# ISS_ISP5_SYS1 register map
Vendor: Texas Instruments
Peripheral module from a debugger description file (folder omap4430).
Registers are 32-bit, access not given, reset 0x0 unless marked. A register's access mark holds for its fields unless they carry their own. Offsets are as the file gives them; lines under a group give offsets from that group; [hi:lo] are bit positions; {n}, {i} and the like mark numbered series; 'fields as' and 'values as' point back to an identical list; <NAME> marks a mode.

## ISS_ISP5_SYS1 (part 1 of 2)
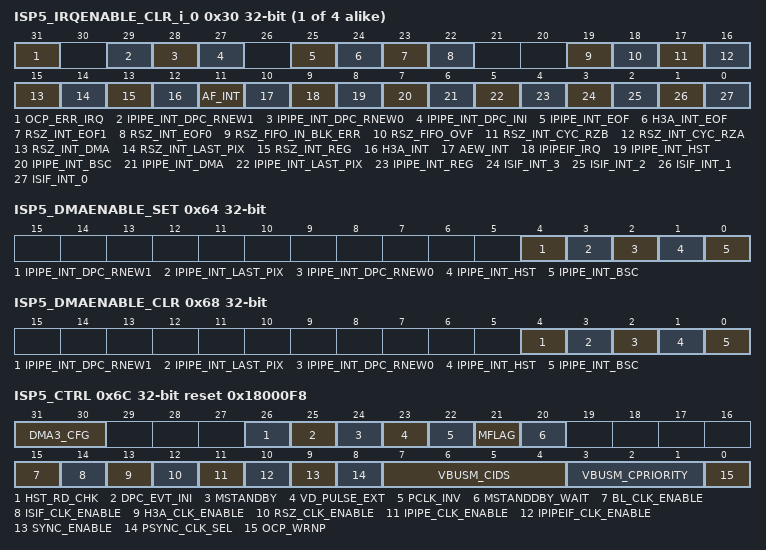
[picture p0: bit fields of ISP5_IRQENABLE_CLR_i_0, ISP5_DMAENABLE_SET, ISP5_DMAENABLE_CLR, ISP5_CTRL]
{0x30+0x10*i} ISP5_IRQENABLE_CLR_i_{i} (i=0..3) — Per-event interrupt enable bit vector. Write 1 to clear (disable interrupt). Readout equal to corresponding _SET register. The ISP outputs four interrupt lines, ISP_IRQ0 to ISP_IRQ3. Any internal ISP event can be merged on the four lines. A same event must be enabled on only one interrupt line.
  [31] OCP_ERR_IRQ — An OCP error has been received on the ISP master port. (access RW W1toClr)
    0=OCP_ERR_IRQ_0_w (No action); 1=OCP_ERR_IRQ_1_w (Disable interrupt); 1=OCP_ERR_IRQ_1_r (Interrupt enabled); 0=OCP_ERR_IRQ_0_r (Interrupt disabled (masked))
  [29] IPIPE_INT_DPC_RNEW1 — (access RW W1toClr)
    0=IPIPE_INT_DPC_RNEW1_0_w (No action); 1=IPIPE_INT_DPC_RNEW1_1_w (Disable interrupt); 1=IPIPE_INT_DPC_RNEW1_1_r (Interrupt enabled); 0=IPIPE_INT_DPC_RNEW1_0_r (Interrupt disabled (masked))
  [28] IPIPE_INT_DPC_RNEW0 — (access RW W1toClr)
    0=IPIPE_INT_DPC_RNEW0_0_w (No action); 1=IPIPE_INT_DPC_RNEW0_1_w (Disable interrupt); 1=IPIPE_INT_DPC_RNEW0_1_r (Interrupt enabled); 0=IPIPE_INT_DPC_RNEW0_0_r (Interrupt disabled (masked))
  [27] IPIPE_INT_DPC_INI — (access RW W1toClr)
    0=IPIPE_INT_DPC_INI_0_w (No action); 1=IPIPE_INT_DPC_INI_1_w (Disable interrupt); 1=IPIPE_INT_DPC_INI_1_r (Interrupt enabled); 0=IPIPE_INT_DPC_INI_0_r (Interrupt disabled (masked))
  [25] IPIPE_INT_EOF rw
    0=IPIPE_INT_EOF_0_w (No action); 1=IPIPE_INT_EOF_1_w (Disable interrupt); 1=IPIPE_INT_EOF_1_r (Interrupt enabled); 0=IPIPE_INT_EOF_0_r (Interrupt disabled (masked))
  [24] H3A_INT_EOF rw
    0=H3A_INT_EOF_0_w (No action); 1=H3A_INT_EOF_1_w (Disable interrupt); 1=H3A_INT_EOF_1_r (Interrupt enabled); 0=H3A_INT_EOF_0_r (Interrupt disabled (masked))
  [23] RSZ_INT_EOF1 rw — RESIZER module event: This event signals that the BL has received the EOF signal from the resizer B engine which happens one the last transfer in the frame has happened. Note that because the BL has FIFOs it may take some additional time before true data transfer completion to memory.
    0=RSZ_INT_EOF1_0_w (No action); 1=RSZ_INT_EOF1_1_w (Disable interrupt); 1=RSZ_INT_EOF1_1_r (Interrupt enabled); 0=RSZ_INT_EOF1_0_r (Interrupt disabled (masked))
  [22] RSZ_INT_EOF0 rw — RESIZER module event: This event signals that the BL has received the EOF signal from the resizer A engine which happens one the last transfer in the frame has happened. Note that because the BL has FIFOs it may take some additional time before true data transfer completion to memory.
    0=RSZ_INT_EOF0_0_w (No action); 1=RSZ_INT_EOF0_1_w (Disable interrupt); 1=RSZ_INT_EOF0_1_r (Interrupt enabled); 0=RSZ_INT_EOF0_0_r (Interrupt disabled (masked))
  [19] RSZ_FIFO_IN_BLK_ERR — This event signals that the minimum vertical blanking period has not been respected causing errors in the input data buffering submodule. This event will be triggered when the rsz_int_reg event of frame N is triggered before the rsz_int_dma of frame N + 1. This event would typically happen at the transition between two frames because there is not enough vertical blanking between frames: the firmware must take care to ensure enough vertical blanking. The hardware cannot recover from this error. It will be required to perform a reset of the IP. (access RW W1toClr)
    0=RSZ_FIFO_IN_BLK_ERR_0_w (No action); 1=RSZ_FIFO_IN_BLK_ERR_1_w (Disable interrupt); 1=RSZ_FIFO_IN_BLK_ERR_1_r (Interrupt enabled); 0=RSZ_FIFO_IN_BLK_ERR_0_r (Interrupt disabled (masked))
  [18] RSZ_FIFO_OVF — RESIZER module event: This event signals that overflow happened in the input data buffering submodule or in the RSZ output interface.. This event would typically happen because the video port pixel clock is too high. (access RW W1toClr)
    0=RSZ_FIFO_OVF_0_w (No action); 1=RSZ_FIFO_OVF_1_w (Disable interrupt); 1=RSZ_FIFO_OVF_1_r (Interrupt enabled); 0=RSZ_FIFO_OVF_0_r (Interrupt disabled (masked))
  [17] RSZ_INT_CYC_RZB — RESIZER module event: This event is the circular interrupt for RESIZER #B. An event can be triggered every time that RSZ_IRQ_RZB output lines have been written out to the RZB_SDR_Y buffer. The range can go from 1 to 8192 lines. Usually, this value should be such that the circular buffer vertical size (set by the RZB_SDR_Y_PTR_E register) is a multiple of RSZ_IRQ_RZB. Note that at the time the interrupt is triggered, the actual data write has not taken place. It may take a few hundred of cycles to complete the data write into system memory. This is not an issue since the start of the buffer is read first. (access RW W1toClr)
    0=RSZ_INT_CYC_RZB_0_w (No action); 1=RSZ_INT_CYC_RZB_1_w (Disable interrupt); 1=RSZ_INT_CYC_RZB_1_r (Interrupt enabled); 0=RSZ_INT_CYC_RZB_0_r (Interrupt disabled (masked))
  [16] RSZ_INT_CYC_RZA — RESIZER module event: This event is the circular interrupt for RESIZER #A. An event can be triggered every time that RSZ_IRQ_RZA output lines have been written out to the RZA_SDR_Y buffer. The range can go from 1 to 8192 lines. Usually, the circular buffer vertical size (set by the RZA_SDR_Y_PTR_E register) should be a multiple of RSZ_IRQ_RZA. Note that at the time the interrupt is triggered, the actual data write has not taken place. It may take a few hundred of cycles to complete the data write into system memory. This is not an issue since the start of the buffer is read first. (access RW W1toClr)
    0=RSZ_INT_CYC_RZA_0_w (No action); 1=RSZ_INT_CYC_RZA_1_w (Disable interrupt); 1=RSZ_INT_CYC_RZA_1_r (Interrupt enabled); 0=RSZ_INT_CYC_RZA_0_r (Interrupt disabled (masked))
  [15] RSZ_INT_DMA — RESIZER module event: This event is triggered when the last EOF (of the two MTC interfaces) is sent out to the BL and that the resizer core has returned to idle. rsz_int_dma is a true indication that all processing is finished for the particular frame on both resizer engines. (access RW W1toClr)
    0=RSZ_INT_DMA_0_w (No action); 1=RSZ_INT_DMA_1_w (Disable interrupt); 1=RSZ_INT_DMA_1_r (Interrupt enabled); 0=RSZ_INT_DMA_0_r (Interrupt disabled (masked))
  [14] RSZ_INT_LAST_PIX — RESIZER module event: This event is triggered when the last pixel of the valid area is received. (access RW W1toClr)
    0=RSZ_INT_LAST_PIX_0_w (No action); 1=RSZ_INT_LAST_PIX_1_w (Disable interrupt); 1=RSZ_INT_LAST_PIX_1_r (Interrupt enabled); 0=RSZ_INT_LAST_PIX_0_r (Interrupt disabled (masked))
  [13] RSZ_INT_REG — RESIZER module event: This event is triggered when the first pixel of the valid area is received. Shadowed registers can be updated at any time but the new value will take effect on the next rsz_int_reg event. (access RW W1toClr)
    0=RSZ_INT_REG_0_w (No action); 1=RSZ_INT_REG_1_w (Disable interrupt); 1=RSZ_INT_REG_1_r (Interrupt enabled); 0=RSZ_INT_REG_0_r (Interrupt disabled (masked))
  [12] H3A_INT — (access RW W1toClr)
    0=H3A_INT_0_w (No action); 1=H3A_INT_1_w (Disable interrupt); 1=H3A_INT_1_r (Interrupt enabled); 0=H3A_INT_0_r (Interrupt disabled (masked))
  [11] AF_INT — (access RW W1toClr)
    0=AF_INT_0_w (No action); 1=AF_INT_1_w (Disable interrupt); 1=AF_INT_1_r (Interrupt enabled); 0=AF_INT_0_r (Interrupt disabled (masked))
  [10] AEW_INT — (access RW W1toClr)
    0=AEW_INT_0_w (No action); 1=AEW_INT_1_w (Disable interrupt); 1=AEW_INT_1_r (Interrupt enabled); 0=AEW_INT_0_r (Interrupt disabled (masked))
  [9] IPIPEIF_IRQ — IPIPEIF module interrupt (access RW W1toClr)
    0=IPIPEIF_IRQ_0_w (No action); 1=IPIPEIF_IRQ_1_w (Disable interrupt); 1=IPIPEIF_IRQ_1_r (Interrupt enabled); 0=IPIPEIF_IRQ_0_r (Interrupt disabled (masked))
  [8] IPIPE_INT_HST — (access RW W1toClr)
    0=IPIPE_INT_HST_0_w (No action); 1=IPIPE_INT_HST_1_w (Disable interrupt); 1=IPIPE_INT_HST_1_r (Interrupt enabled); 0=IPIPE_INT_HST_0_r (Interrupt disabled (masked))
  [7] IPIPE_INT_BSC — (access RW W1toClr)
    0=IPIPE_INT_BSC_0_w (No action); 1=IPIPE_INT_BSC_1_w (Disable interrupt); 1=IPIPE_INT_BSC_1_r (Interrupt enabled); 0=IPIPE_INT_BSC_0_r (Interrupt disabled (masked))
  [6] IPIPE_INT_DMA — (access RW W1toClr)
    0=IPIPE_INT_DMA_0_w (No action); 1=IPIPE_INT_DMA_1_w (Disable interrupt); 1=IPIPE_INT_DMA_1_r (Interrupt enabled); 0=IPIPE_INT_DMA_0_r (Interrupt disabled (masked))
  [5] IPIPE_INT_LAST_PIX — (access RW W1toClr)
    0=IPIPE_INT_LAST_PIX_0_w (No action); 1=IPIPE_INT_LAST_PIX_1_w (Disable interrupt); 1=IPIPE_INT_LAST_PIX_1_r (Interrupt enabled); 0=IPIPE_INT_LAST_PIX_0_r (Interrupt disabled (masked))
  [4] IPIPE_INT_REG — (access RW W1toClr)
    0=IPIPE_INT_REG_0_w (No action); 1=IPIPE_INT_REG_1_w (Disable interrupt); 1=IPIPE_INT_REG_1_r (Interrupt enabled); 0=IPIPE_INT_REG_0_r (Interrupt disabled (masked))
  [3] ISIF_INT_3 — Set this bit to disable the LSC interrupt issued by the 2D-LSC block. Four types of 2D-LSC can be generated and mapped to the INT_3 line. For more information, see, (access RW W1toClr)
    0=ISIF_INT_3_0_w (No action); 1=ISIF_INT_3_1_w (Disable interrupt); 1=ISIF_INT_3_1_r (Interrupt enabled); 0=ISIF_INT_3_0_r (Interrupt disabled (masked))
  [2] ISIF_INT_2 — VD interrupt 2 event. Set this bit to disable the interrupt mapped to the INT_2 line. This interrupt is set based on the VD pulse position after receiving a configured number of horizontal pulse signals. For more information, see, (access RW W1toClr)
    0=ISIF_INT_2_0_w (No action); 1=ISIF_INT_2_1_w (Disable interrupt); 1=ISIF_INT_2_1_r (Interrupt enabled); 0=ISIF_INT_2_0_r (Interrupt disabled (masked))
  [1] ISIF_INT_1 — VD interrupt 1 event. Set this bit to disable the interrupt mapped to the INT_1 line. This interrupt is set based on the VD pulse position after receiving a configured number of horizontal pulse signals. For more information, see, (access RW W1toClr)
    0=ISIF_INT_1_0_w (No action); 1=ISIF_INT_1_1_w (Disable interrupt); 1=ISIF_INT_1_1_r (Interrupt enabled); 0=ISIF_INT_1_0_r (Interrupt disabled (masked))
  [0] ISIF_INT_0 — VD interrupt 0 event. Set this bit to disable the interrupt mapped to the INT_0 line. This interrupt is set based on the VD pulse position after receiving a configured number of horizontal pulse signals. For more information, see, (access RW W1toClr)
    0=ISIF_INT_0_0_w (No action); 1=ISIF_INT_0_1_w (Disable interrupt); 1=ISIF_INT_0_1_r (Interrupt enabled); 0=ISIF_INT_0_0_r (Interrupt disabled (masked))
0x64 ISP5_DMAENABLE_SET — Per-line DMA enable bit vector Write 1 to set (enable DMA request generation). Readout equal to corresponding _CLR register.
  [4] IPIPE_INT_DPC_RNEW1 — Enable for ISP DMA request generation on line #2 This DMA request must be set to transfer the DPC data from memory to the IPIPE internal RAM. (access RW W1toSet)
    0=IPIPE_INT_DPC_RNEW1_0_w (No action); 1=IPIPE_INT_DPC_RNEW1_1_w (Enable DMA); 1=IPIPE_INT_DPC_RNEW1_1_r (DMA enabled); 0=IPIPE_INT_DPC_RNEW1_0_r (DMA disabled)
  [3] IPIPE_INT_LAST_PIX — Enable for ISP DMA request generation on line #3 This DMA request must be set to transfer the GAMMA data from memory to the IPIPE internal RAM or to initialize the DPC table. One must set the ISP5_CTRL.DMA3_CFG register before enabling this DMA request. (access RW W1toSet)
    0=IPIPE_INT_LAST_PIX_0_w (No action); 1=IPIPE_INT_LAST_PIX_1_w (Enable DMA); 1=IPIPE_INT_LAST_PIX_1_r (DMA enabled); 0=IPIPE_INT_LAST_PIX_0_r (DMA disabled)
  [2] IPIPE_INT_DPC_RNEW0 — Enable for ISP DMA request generation on line #2 This DMA request must be set to transfer the DPC data from memory to the IPIPE internal RAM. (access RW W1toSet)
    0=IPIPE_INT_DPC_RNEW0_0_w (No action); 1=IPIPE_INT_DPC_RNEW0_1_w (Enable DMA); 1=IPIPE_INT_DPC_RNEW0_1_r (DMA enabled); 0=IPIPE_INT_DPC_RNEW0_0_r (DMA disabled)
  [1] IPIPE_INT_HST — Enable for ISP DMA request generation on line #1 This DMA request must be set to transfer the HIST data from the IPIPE internal RAM to memory. (access RW W1toSet)
    0=IPIPE_INT_HST_0_w (No action); 1=IPIPE_INT_HST_1_w (Enable DMA); 1=IPIPE_INT_HST_1_r (DMA enabled); 0=IPIPE_INT_HST_0_r (DMA disabled)
  [0] IPIPE_INT_BSC — Enable for ISP DMA request generation on line #0 This DMA request must be set to transfer the BSC data from the IPIPE internal RAM to memory. (access RW W1toSet)
    0=IPIPE_INT_BSC_0_w (No action); 1=IPIPE_INT_BSC_1_w (Enable DMA); 1=IPIPE_INT_BSC_1_r (DMA enabled); 0=IPIPE_INT_BSC_0_r (DMA disabled)
0x68 ISP5_DMAENABLE_CLR — Per-line DMA clear bit vector Write 1 to clear (disable DMA request generation). Readout equal to corresponding _SET register.
  [4] IPIPE_INT_DPC_RNEW1 — Clear for ISP DMA request generation on line ISS_DMA2. This DMA request must be set to transfer the DPC data from memory to the IPIPE internal RAM. (access RW W1toClr)
    0=IPIPE_INT_DPC_RNEW1_0_w (No action); 1=IPIPE_INT_DPC_RNEW1_1_w (Disable DMA); 1=IPIPE_INT_DPC_RNEW1_1_r (DMA enabled); 0=IPIPE_INT_DPC_RNEW1_0_r (DMA disabled)
  [3] IPIPE_INT_LAST_PIX — Clear for ISP DMA request generation on ISS_DMA3. This DMA request must be set to transfer the GAMMA data from memory to the IPIPE internal RAM. (access RW W1toClr)
    0=IPIPE_INT_LAST_PIX_0_w (No action); 1=IPIPE_INT_LAST_PIX_1_w (Disable DMA); 1=IPIPE_INT_LAST_PIX_1_r (DMA enabled); 0=IPIPE_INT_LAST_PIX_0_r (DMA disabled)
  [2] IPIPE_INT_DPC_RNEW0 — Clear for ISP DMA request generation on ISS_DMA2. This DMA request must be set to transfer the DPC data from memory to the IPIPE internal RAM. (access RW W1toClr)
    0=IPIPE_INT_DPC_RNEW0_0_w (No action); 1=IPIPE_INT_DPC_RNEW0_1_w (Disable DMA); 1=IPIPE_INT_DPC_RNEW0_1_r (DMA enabled); 0=IPIPE_INT_DPC_RNEW0_0_r (DMA disabled)
  [1] IPIPE_INT_HST — Clear for ISP DMA request generation on ISS_DMA1. This DMA request must be set to transfer the HIST data from the IPIPE internal RAM to memory. (access RW W1toClr)
    0=IPIPE_INT_HST_0_w (No action); 1=IPIPE_INT_HST_1_w (Disable DMA); 1=IPIPE_INT_HST_1_r (DMA enabled); 0=IPIPE_INT_HST_0_r (DMA disabled)
  [0] IPIPE_INT_BSC — Clear for ISP DMA request generation on ISS_DMA0. This DMA request must be set to transfer the BSC data from the IPIPE internal RAM to memory. (access RW W1toClr)
    0=IPIPE_INT_BSC_0_w (No action); 1=IPIPE_INT_BSC_1_w (Disable DMA); 1=IPIPE_INT_BSC_1_r (DMA enabled); 0=IPIPE_INT_BSC_0_r (DMA disabled)
0x6C ISP5_CTRL access per field reset 0x18000F8 (reset mask 0xFFEFFFFF) — ISP5 CONTROL REGISTER
  [31:30] DMA3_CFG rw — This bit field selects the DMA transfer configuration which is used with the ISS_DMA3 DMA request signal. This DMA request is generated from IPIPE_INT_LAST_PIXEL event. One can choose to use this DMA request to transfer the DPC initialization data, the gamma table, or both.
    0=No DMA request associated with ISS_DMA3; 1=DPC DMA request associated with ISS_DMA3. Expected DMA transfer size is 2KB in the range 0x8000-0x87FF. DPC_EVT_INI must be set to 0.; 3=DPC + GAMMA DMA request associated with ISS_DMA3. Expected DMA transfer size is 8KB in the range 0x8000-0x87FF and 0xA800-0xBFFF. DPC_EVT_INI must be set to 0.; 2=GAMMA DMA request associated with ISS_DMA3. Expected DMA transfer size is 6KB in the range 0xA800-0xBFFF.
  [26] HST_RD_CHK rw — When the HISTOGRAM computation is enabled and the HST DMA request is not used to read out the data, this register ensures that the data is read fast enough, else an interruptISP5_IRQSTATUS2_i[5] IPIPE_HST_ERR is triggered. The hardware sets automatically this bit to 1 when software can start reading the memory. .
    0=HST_RD_CHK_0_w (Clears the signal to avoid error generation. The software must write this bit to 0 after the last data read.); 1=HST_RD_CHK_1_w (Reserved); 1=HST_RD_CHK_1_r (The MPU can read the data from the memory. Needs to complete fast enough to avoid the interrupt generation.); 0=HST_RD_CHK_0_r (No interrupt generation can happen)
  [25] DPC_EVT_INI rw — Select the IPIPE module event to be used to generate the DMA requests for the DPC submodule.
    0=IPIPE_INT_LAST_PIX event is selected; 1=IPIPE_INT_DPC_INI event is selected
  [24] MSTANDBY rw — MStandby signal assertion and de-assertion control for power management transitions. After software reset, this bit is asserted. Write '1' to transition from normal mode to idle mode. The firmware needs to ensure that no more ISP processing is ongoing before setting up this bit. Write '0' to transition from idle mode to normal mode. The software should poll ISP5_CTRL.MSTANDBY_WAIT = 0 after writing ISP5_CTRL.MSTANDBY = 0 in a transition from idle to normal mode.
    0=De-assert MStandby signal. May not be immediate due to power management handshaking btw the MStandby and Wait signals.; 1=Assert MStandby signal
  [23] VD_PULSE_EXT rw — VD pulse extension enable This bit enables or disables the VD extension bridge. By default, the bridge is enabled. At ISS level, it is expected that ISP5_CTRL.VD_PULSE_EXT = 1 when the VPORT gets data from the CSI2 RX module and ISP5_CTRL.VD_PULSE_EXT = 0 when the VPORT gets data from the parallel interface or the CCP2 RX module. There must be at least three clock cycles between the time this bit is modified and the HD/VD pulse for start of frame comes.
    0=Disabled; 1=Enabled
  [22] PCLK_INV rw — Pixel clock inversion This bit enables or disables pixel clock inversion. The ISP always samples the data on the rising edge of the pixel clock. Enabling the inversion shifts the resampling period by 1/2 a pixel clock period.
    0=Normal; 1=Inversed
  [21] MFLAG rw — MFlag signal generation control This bit controls how the OCP MFlag signal is generated on the ISS NOC. 0x0: The MFlag value is dynamic. 0x1: The MFlag value is static. The value is set with the ISP5_CTRL[3:1] VBUSM_CPRIORITY.
  [20] MSTANDDBY_WAIT ro — MStandby / Wait power management status bit. The power management framework of the ISP is based on the handshaking of the MStandby and Wait signals. The software is not supposed to write inside the ISP slave port and initiate traffic when ISP5_CTRL.MSTANDBY bit is written. The software can poll this bit to know when Wait signal is deasserted.
    1=MSTANDDBY_WAIT_1_r (MStandby signal is asserted.); 0=MSTANDDBY_WAIT_0_r (MStandby signal is deasserted.)
  [15] BL_CLK_ENABLE rw — BL clock enable
    0=Disable; 1=Enable
  [14] ISIF_CLK_ENABLE rw — ISIF clock enable The ISP will return OCP_ERROR if one tries to program the module MMR or memory when the clock is disabled. There must be at least three clock cycles between the time this bit is modified and the HD/VD pulse for start of frame comes.
    0=Disable; 1=Enable
  [13] H3A_CLK_ENABLE rw — H3A clock enable The ISP will return OCP_ERROR if one tries to program the module MMR or memory when the clock is disabled.
    0=Disable; 1=Enable
  [12] RSZ_CLK_ENABLE rw — RESIZER clock enable The ISP will return OCP_ERROR if one tries to program the module MMR or memory when the clock is disabled.
    0=Disable; 1=Enable
  [11] IPIPE_CLK_ENABLE rw — IPIPE clock enable The ISP will return OCP_ERROR if one tries to program the module MMR or memory when the clock is disabled.
    0=Disable; 1=Enable
  [10] IPIPEIF_CLK_ENABLE rw — IPIPEIF clock enable The ISP will return OCP_ERROR if one tries to program the module MMR or memory when the clock is disabled.
    0=Disable; 1=Enable
  [9] SYNC_ENABLE rw — PCLK Sync module enable. This bit may only be modified when the video port is not receiving data such as when data is read from the IPIPEIF module memory read port.
    0=Disable; 1=Enable
  [8] PSYNC_CLK_SEL rw — PCLK Sync clock select. This bit selects the clock which is used to resynchronize the input pixel clock.
    0=GCK_MMR. Can be used if the input pixel clock is always lower than 100 MHz.; 1=ISS_FCLK. must be used if the pixel clock is higher than 100 MHz.
  [7:4] VBUSM_CIDS rw — BL MAX VBUSM CIDs The BL module supports up to 16 CIDs/tags. This bit field sets up the maximum number of CISs/tags that the BL can use. The actual number of CIDs/tags is setup by VBUSM_CIDS + 1. Tag number 0 to VBUSM_CIDS are used.
  [3:1] VBUSM_CPRIORITY rw — BL VBUSM priority setting
    {v}=Normal Priority VBUSM cpriority[2:0] = {v} (v=4..7); 1=High Priority VBUSM cpriority[2:0] = 1; 0=High Priority VBUSM cpriority[2:0] = 0; 2=Medium Priority VBUSM cpriority[2:0] = 2; 3=Medium Priority VBUSM cpriority[2:0] = 3
  [0] OCP_WRNP rw — ISP OCP master port non-posted write control.
    0=All writes are non posted; 1=All writes are posted
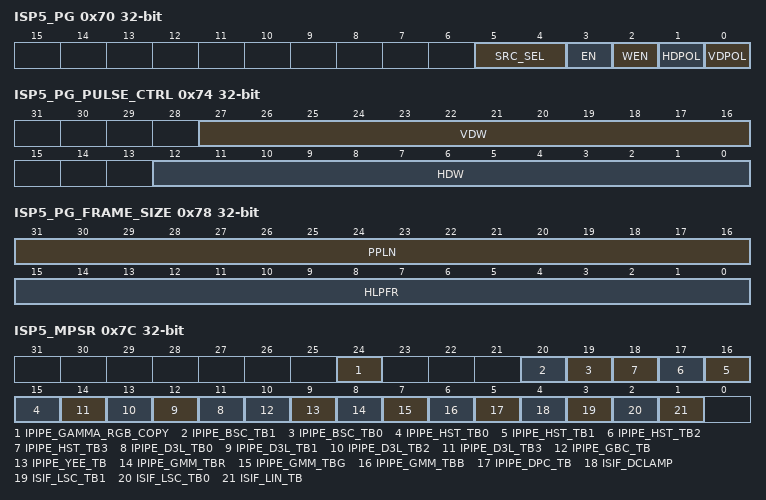
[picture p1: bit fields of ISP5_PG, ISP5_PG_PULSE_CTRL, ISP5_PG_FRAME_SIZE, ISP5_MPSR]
0x70 ISP5_PG access per field — PATTERN GENERATOR REGISTER
  [5:4] SRC_SEL rw — Input mux selection
    0=ISP video port is selected; 3=Pattern generator is selected
  [3] EN rw
    0=Pattern generator off; 1=Enable pattern generator
  [2] WEN rw
    0=WEN is always activated; 1=WEN is on 8 cycles and off 8 cycles
  [1] HDPOL rw
    0=Active high; 1=Active low
  [0] VDPOL rw
    0=Active high; 1=Active low
0x74 ISP5_PG_PULSE_CTRL access per field — PATTERN GENERATOR REGISTER
  [27:16] VDW rw — Pattern generator VD width Width = VDW+1
  [12:0] HDW rw — Pattern generator HD width Width = HDW+1
0x78 ISP5_PG_FRAME_SIZE rw — PATTERN GENERATOR REGISTER
  [31:16] PPLN — Pattern Generator: pixels per line, PPLN+1
  [15:0] HLPFR — Pattern Generator: half lines per frame, HLPFR+1
0x7C ISP5_MPSR access per field — ISP memory access register. One need to pay attention when setting the bit fields in this register such that there is no conflict between the CPU and module accesses. Usually, the ISP modules must have access to the memories and it is only when the ISP is idle (vertical blanking period or module disabled that the CPU can access the memories.
  [24] IPIPE_GAMMA_RGB_COPY rw — GAMMA table RGB Copy This bit must be enable when one wants to use the same Gamma table for the R, G and B color components. When the CPU writes the R table, it is automatically copied to the G and B tables if this bit is set.
    0=Copy disable Independent RGB gamma table; 1=Copy enable Common RGB Gamma table
  [20] IPIPE_BSC_TB1 rw — IPIPE BSC TB1 memory access priority This memory is expected to be read by the CPU or the DMA to get BSC information during vertical blanking period.
    0=MODULE access has higher priority; 1=CPU access has higher priority
  [19] IPIPE_BSC_TB0 rw — IPIPE BSC TB0 memory access priority This memory is expected to be read by the CPU or the DMA to get BSC information during vertical blanking period.
    values as IPIPE_BSC_TB1
  [n+15] IPIPE_HST_TB{n} rw (n=0..3) — IPIPE histogram memory #{n} access priority This memory is expected to be read by the CPU or the DMA to get HST information during vertical blanking period.
    values as IPIPE_BSC_TB1
  [n+11] IPIPE_D3L_TB{n} rw (n=0..3) — D3L TB{n} memory access priority This memory is expected to be written during ISP initialization and potentially updated during vertical blanking periods.
    values as IPIPE_BSC_TB1
  [10] IPIPE_GBC_TB rw — IPIPE GBC TB memory access priority This memory is expected to be written during ISP initialization and potentially updated during vertical blanking periods.
    values as IPIPE_BSC_TB1
  [9] IPIPE_YEE_TB rw — YEE TB memory access priority This memory is expected to be written during ISP initialization and potentially updated during vertical blanking periods.
    values as IPIPE_BSC_TB1
  [8] IPIPE_GMM_TBR rw — IPIPE Gamma LUT R memory arbitration This memory is expected to be written during ISP initialization and potentially updated during vertical blanking periods.
    values as IPIPE_BSC_TB1
  [7] IPIPE_GMM_TBG rw — IPIPE Gamma LUT G memory arbitration This memory is expected to be written during ISP initialization and potentially updated during vertical blanking periods.
    values as IPIPE_BSC_TB1
  [6] IPIPE_GMM_TBB rw — IPIPE Gamma LUT B memory arbitration This memory is expected to be written during ISP initialization and potentially updated during vertical blanking periods.
    values as IPIPE_BSC_TB1
  [5] IPIPE_DPC_TB rw — IPIPE defect pixel memory arbitration This memory is expected to be written during ISP initialization and potentially updated during vertical blanking periods.
    values as IPIPE_BSC_TB1
  [4] ISIF_DCLAMP rw — ISIF DC accumulation memory arbitration This memory is expected to be written during ISP initialization and potentially updated during vertical blanking periods.
    values as IPIPE_BSC_TB1
  [3] ISIF_LSC_TB1 rw — ISIF LSC memory 1 access This memory is expected to be written during ISP initialization and potentially updated during vertical blanking periods.
    0=MODULE has memory access When the module has memory access, the potential concurrent CPU accesses (on the ISP memory map) to read the memory are stalled. The CPU will eventually get back the data during the horizontal or vertical blanking periods when the module is not making access anymore.; 1=CPU has memory access When the CPU has memory access (read or write), it will cause data corruption if the module tries to perform concurrent memory accesses. The module cannot know that the read or write access has not taken place because of CPU accesses.
  [2] ISIF_LSC_TB0 rw — ISIF LSC memory 0 access This memory is expected to be written during ISP initialization and potentially updated during vertical blanking periods.
    0=MODULE has memory access. When the module has memory access, the potential concurrent CPU accesses (on the ISP memory map) to read the memory are stalled. The CPU will eventually get back the data during the horizontal or vertical blanking periods when the module is not making access anymore.; 1=CPU has memory access When the CPU has memory access (read or write), it will cause data corruption if the module tries to perform concurrent memory accesses. The module cannot know that the read or write access has not taken place because of CPU accesses.
  [1] ISIF_LIN_TB rw — ISIF linearity compensation memory arbitration This memory is expected to be written during ISP initialization and potentially updated during vertical blanking periods.
    values as IPIPE_BSC_TB1
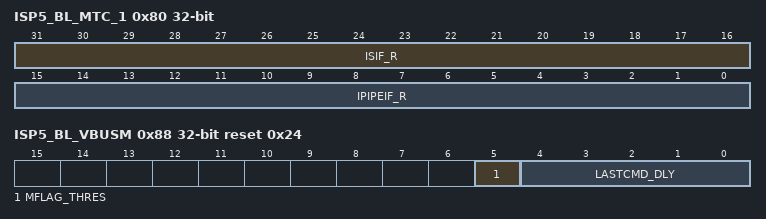
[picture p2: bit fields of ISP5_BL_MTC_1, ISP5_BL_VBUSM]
0x80 ISP5_BL_MTC_1 rw — MEMORY REQUEST MINIMUM INTERVAL REGISTER
  [31:16] ISIF_R — Sets the minimum interval btw two consecutive memory requests for the ISIF-Read port. Specified in number of interface clock cycles.
  [15:0] IPIPEIF_R — Sets the minimum interval btw two consecutive memory requests for the IPIPEIF-Read port. Specified in number of interface clock cycles.
0x84 ISP5_BL_MTC_2 access per field — MEMORY REQUEST MINIMUM INTERVAL REGISTER
  [31:16] H3A_W rw — Sets the minimum interval btw two consecutive memory requests for the H3A-Write port. Specified in number of interface clock cycles.
0x88 ISP5_BL_VBUSM access per field reset 0x24 — BL VBUSM TUNING REGISTER The settings in the register are static and not expected to be modified dynamically.
  [5] MFLAG_THRES rw — MFLAG Threshold value The value of this bit field is a threshold which is compared to the MFlag output of the ISP5. If the BL MFlag signal is greater or equal to this threshold the last beat of the VBUSM command is delayed by ISP5_BL_VBUSM[4:0] LASTCMD_DLY cycles. Only values 0, 1 are valid, the least significant bit is tied off to 1 to make a 2-bit field.
    0=Thres = 1; 1=Thres = 3
  [4:0] LASTCMD_DLY rw — The value of this bit field represents a delay expressed in cycles (L3 clock). This value is used to delay the last beat of the VBUSM command such that the ISP does not loose arbitration at the ISS level because the BL does not generate back to back requests by default. The last beat is delayed until the counter expires or the new request is accepted. This delay is used when the MFlag output of the ISP is greater or equal to ISP5_BL_VBUSM[5] MFLAG_THRES. One can set this value to 0 to disable the last command beat delay.
